# STM32H745_CM7 register map
File version: 2.0
CPU: CM7 r0p1, little endian, MPU, FPU, 4 interrupt priority bits
Registers are 32-bit, read-write, reset 0x0 unless marked. A register's access mark holds for its fields unless they carry their own. Offsets are from the block's base; [hi:lo] are bit positions; {n}, {i} and the like mark numbered series; 'fields as' and 'values as' point back to an identical list.

## TIM6 — Basic timers
Base 0x40001000
Same registers: TIM7 0x40001400
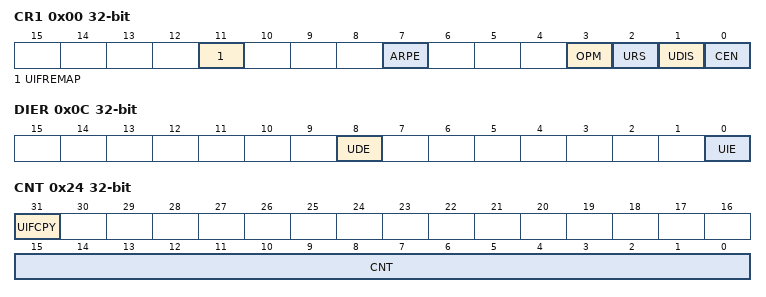
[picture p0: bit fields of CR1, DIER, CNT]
0x00 CR1 — control register 1
  [11] UIFREMAP — UIF status bit remapping
  [7] ARPE — Auto-reload preload enable
  [3] OPM — One-pulse mode
  [2] URS — Update request source
  [1] UDIS — Update disable
  [0] CEN — Counter enable
0x04 CR2 — control register 2
  [6:4] MMS — Master mode selection
0x0C DIER — DMA/Interrupt enable register
  [8] UDE — Update DMA request enable
  [0] UIE — Update interrupt enable
0x10 SR — status register
  [0] UIF — Update interrupt flag
0x14 EGR wo — event generation register
  [0] UG — Update generation
0x24 CNT — counter
  [31] UIFCPY — UIF Copy
  [15:0] CNT — Low counter value
0x28 PSC — prescaler
  [15:0] PSC — Prescaler value
0x2C ARR — auto-reload register
  [15:0] ARR — Low Auto-reload value

## RAMECC1 — ECC controller is associated to each RAM area
Base 0x52009000
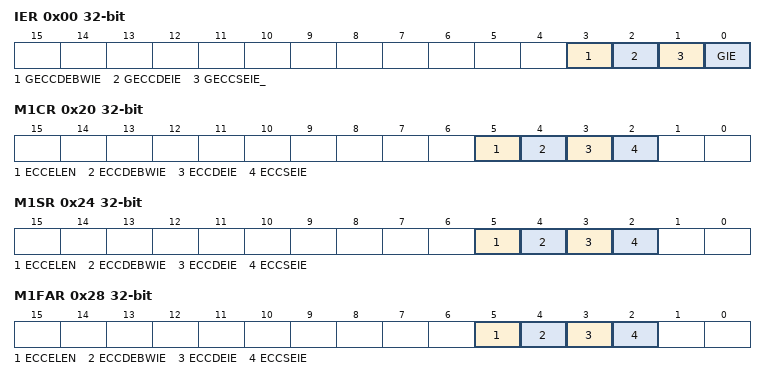
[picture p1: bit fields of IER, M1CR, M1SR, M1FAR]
0x00 IER — RAMECC interrupt enable register
  [3] GECCDEBWIE — Global ECC double error on byte write (BW) interrupt enable
  [2] GECCDEIE — Global ECC double error interrupt enable
  [1] GECCSEIE_ — Global ECC single error interrupt enable
  [0] GIE — Global interrupt enable
0x20 M1CR — RAMECC monitor x configuration register
  [5] ECCELEN — ECC error latching enable
  [4] ECCDEBWIE — ECC double error on byte write (BW) interrupt enable
  [3] ECCDEIE — ECC double error interrupt enable
  [2] ECCSEIE — ECC single error interrupt enable
0x24 M1SR — RAMECC monitor x status register
  fields as M1CR
0x28 M1FAR — RAMECC monitor x failing address register
  fields as M1CR
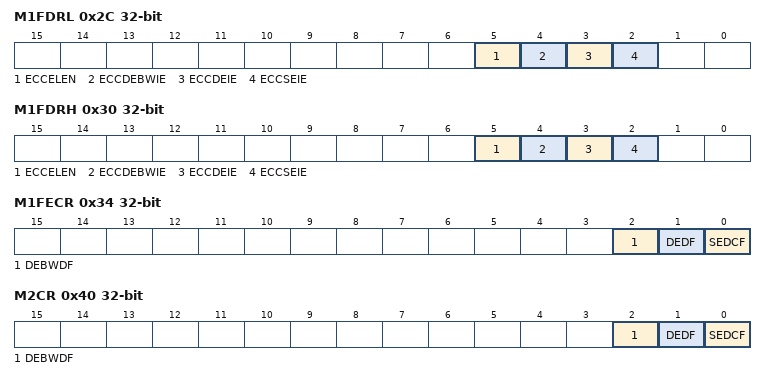
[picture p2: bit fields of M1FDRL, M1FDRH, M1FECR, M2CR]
0x2C M1FDRL — RAMECC monitor x failing data low register
  fields as M1CR
0x30 M1FDRH — RAMECC monitor x failing data high register
  fields as M1CR
0x34 M1FECR — RAMECC monitor x failing ECC error code register
  [2] DEBWDF — ECC double error on byte write (BW) detected flag
  [1] DEDF — ECC double error detected flag
  [0] SEDCF — ECC single error detected and corrected flag
0x40 M2CR — RAMECC monitor x configuration register
  fields as M1FECR
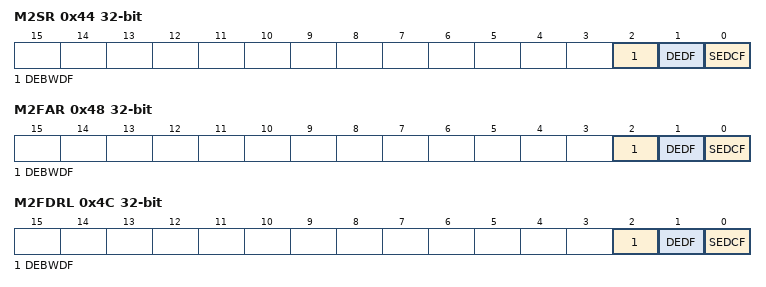
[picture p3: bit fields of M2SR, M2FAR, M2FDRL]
0x44 M2SR — RAMECC monitor x status register
  fields as M1FECR
0x48 M2FAR — RAMECC monitor x failing address register
  fields as M1FECR
0x4C M2FDRL — RAMECC monitor x failing data low register
  fields as M1FECR
0x50 M2FDRH ro — RAMECC monitor x failing data high register
  [31:0] FADD — ECC error failing address
0x58 M2FECR ro — RAMECC monitor x failing ECC error code register
  [31:0] FADD — ECC error failing address
0x60 M3CR ro — RAMECC monitor x configuration register
  [31:0] FADD — ECC error failing address
0x64 M3SR ro — RAMECC monitor x status register
  [31:0] FADD — ECC error failing address
0x68 M3FAR — RAMECC monitor x failing address register
  [31:0] FADD — ECC error failing address
0x6C M3FDRL ro — RAMECC monitor x failing data low register
  [31:0] FDATAL — Failing data low
0x70 M3FDRH ro — RAMECC monitor x failing data high register
  [31:0] FDATAL — Failing data low
0x7C M3FECR ro — RAMECC monitor x failing ECC error code register
  [31:0] FDATAL — Failing data low
0x80 M4CR ro — RAMECC monitor x configuration register
  [31:0] FDATAL — Failing data low
0x84 M4SR ro — RAMECC monitor x status register
  [31:0] FDATAL — Failing data low
0x88 M4FAR ro — RAMECC monitor x failing address register
  [31:0] FDATAH — Failing data high (64-bit memory)
0x8C M4FDRL — RAMECC monitor x failing data low register
  [31:0] FDATAH — Failing data high (64-bit memory)
0x90 M4FDRH ro — RAMECC monitor x failing data high register
  [31:0] FDATAH — Failing data high (64-bit memory)
0x90 M4FECR ro (alternate view of M4FDRH) — RAMECC monitor x failing ECC error code register
  [31:0] FDATAH — Failing data high (64-bit memory)
0xA0 M5CR ro — RAMECC monitor x configuration register
  [31:0] FEC — Failing error code
0xA4 M5SR — RAMECC monitor x status register
  [31:0] FEC — Failing error code
0xA8 M5FAR — RAMECC monitor x failing address register
  [31:0] FEC — Failing error code
0xAC M5FDRL ro — RAMECC monitor x failing data low register
  [31:0] FEC — Failing error code
0xB0 M5FDRH ro — RAMECC monitor x failing data high register
  [31:0] FEC — Failing error code
0xB4 M5FECR ro — RAMECC monitor x failing ECC error code register
  [31:0] FEC — Failing error code

## RAMECC2 — ECC controller is associated to each RAM area
Base 0x48023000
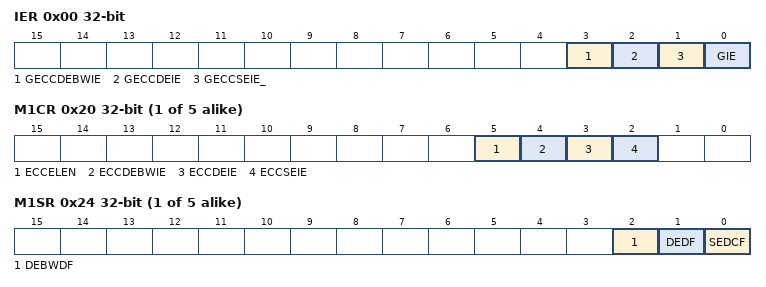
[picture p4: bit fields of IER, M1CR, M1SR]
0x00 IER — RAMECC interrupt enable register
  [3] GECCDEBWIE — Global ECC double error on byte write (BW) interrupt enable
  [2] GECCDEIE — Global ECC double error interrupt enable
  [1] GECCSEIE_ — Global ECC single error interrupt enable
  [0] GIE — Global interrupt enable
{0x0+0x20*i} M{i}CR (i=1..5) — RAMECC monitor x configuration register
  [5] ECCELEN — ECC error latching enable
  [4] ECCDEBWIE — ECC double error on byte write (BW) interrupt enable
  [3] ECCDEIE — ECC double error interrupt enable
  [2] ECCSEIE — ECC single error interrupt enable
{0x4+0x20*i} M{i}SR (i=1..5) — RAMECC monitor x status register
  [2] DEBWDF — ECC double error on byte write (BW) detected flag
  [1] DEDF — ECC double error detected flag
  [0] SEDCF — ECC single error detected and corrected flag
{0x8+0x20*i} M{i}FAR ro (i=1..4) — RAMECC monitor x failing address register
  [31:0] FADD — ECC error failing address
{0xC+0x20*i} M{i}FDRL ro (i=1..5) — RAMECC monitor x failing data low register
  [31:0] FDATAL — Failing data low
0x30 M1FDRH ro — RAMECC monitor x failing data high register
  [31:0] FDATAH — Failing data high (64-bit memory)
0x34 M1FECR — RAMECC monitor x failing ECC error code register
  [31:0] FEC — Failing error code
0x50 M2FDRH — RAMECC monitor x failing data high register
  [31:0] FDATAH — Failing data high (64-bit memory)
0x58 M2FECR — RAMECC monitor x failing ECC error code register
  [31:0] FEC — Failing error code
0x70 M3FDRH ro — RAMECC monitor x failing data high register
  [31:0] FDATAH — Failing data high (64-bit memory)
0x7C M3FECR ro — RAMECC monitor x failing ECC error code register
  [31:0] FEC — Failing error code
0x90 M4FDRH ro — RAMECC monitor x failing data high register
  [31:0] FDATAH — Failing data high (64-bit memory)
0x90 M4FECR ro (alternate view of M4FDRH) — RAMECC monitor x failing ECC error code register
  [31:0] FEC — Failing error code
0xA8 M5FAR — RAMECC monitor x failing address register
  [31:0] FADD — ECC error failing address
0xB0 M5FDRH ro — RAMECC monitor x failing data high register
  [31:0] FEC — Failing error code
0xB4 M5FECR ro — RAMECC monitor x failing ECC error code register
  [31:0] FEC — Failing error code

## RAMECC3 — ECC controller is associated to each RAM area
Base 0x58027000
Registers as RAMECC2, without M{n}CR (n=3..5), M{n}SR (n=3..5), M{n}FAR (n=3..5), M{n}FDRL (n=3..5), M{n}FDRH (n=3..5), M{n}FECR (n=3..5).

## ART — accelerator - control register (ART_CTR)
Base 0x40024400
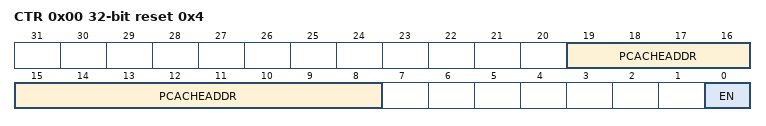
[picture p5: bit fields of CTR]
0x00 CTR reset 0x4 — control register
  [19:8] PCACHEADDR — Cacheable page index
  [0] EN — Cache enable
